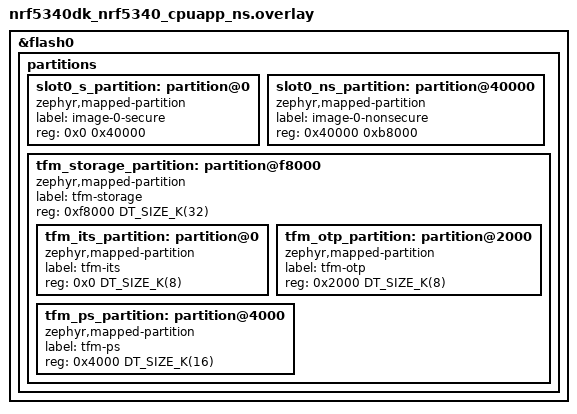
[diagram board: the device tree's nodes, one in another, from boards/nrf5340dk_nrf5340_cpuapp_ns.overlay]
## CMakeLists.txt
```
#
# Copyright (c) 2021 Nordic Semiconductor ASA
#
# SPDX-License-Identifier: LicenseRef-Nordic-5-Clause
#

cmake_minimum_required(VERSION 3.20.0)

find_package(Zephyr REQUIRED HINTS $ENV{ZEPHYR_BASE})

project(persistent_key)

target_sources(app PRIVATE
  src/main.c
  src/init.c
)
```

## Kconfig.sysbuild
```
#
# Copyright (c) 2025 Nordic Semiconductor
#
# SPDX-License-Identifier: LicenseRef-Nordic-5-Clause
#

config PARTITION_MANAGER
	default n if !(SOC_SERIES_NRF91 && BOARD_IS_NON_SECURE)

source "share/sysbuild/Kconfig"
```

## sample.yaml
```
sample:
  description: |
    This sample demonstrates persistent key usage using the PSA Crypto API.
  name: Persistent key usage sample

common:
  sysbuild: true
  tags:
    - introduction
    - psa
    - sysbuild
    - ci_samples_crypto
    - crypto
  harness: console
  harness_config:
    type: multi_line
    regex:
      - ".*Example finished successfully!.*"

tests:
  sample.persistent_key_usage.tf-m:
    tags:
      - ci_samples_tfm
    platform_allow:
      - nrf5340dk/nrf5340/cpuapp/ns
      - nrf54l15dk/nrf54l15/cpuapp/ns
      - nrf54l15dk/nrf54l10/cpuapp/ns
      - nrf54lm20dk/nrf54lm20a/cpuapp/ns
      - nrf54lm20dk/nrf54lm20b/cpuapp/ns
      - nrf54lv10dk/nrf54lv10a/cpuapp/ns
      - nrf54lc10dk/nrf54lc10a/cpuapp/ns
      - nrf7120dk/nrf7120/cpuapp/ns
      - nrf9151dk/nrf9151/ns
    integration_platforms:
      - nrf5340dk/nrf5340/cpuapp/ns
      - nrf54l15dk/nrf54l15/cpuapp/ns
      - nrf54lm20dk/nrf54lm20a/cpuapp/ns
      - nrf54lm20dk/nrf54lm20b/cpuapp/ns
      - nrf54lv10dk/nrf54lv10a/cpuapp/ns
      - nrf54lc10dk/nrf54lc10a/cpuapp/ns
      - nrf7120dk/nrf7120/cpuapp/ns
      - nrf9151dk/nrf9151/ns
  sample.persistent_key_usage.ironside_se:
    tags:
      - ci_samples_sdfw
    platform_allow:
      - nrf54h20dk/nrf54h20/cpuapp
    integration_platforms:
      - nrf54h20dk/nrf54h20/cpuapp
  sample.persistent_key_usage.secure_storage:
    platform_allow:
      - nrf52840dk/nrf52840
      - nrf5340dk/nrf5340/cpuapp
      - nrf9151dk/nrf9151
      - nrf54l15dk/nrf54l15/cpuapp
      - nrf54lm20dk/nrf54lm20a/cpuapp
      - nrf54lm20dk/nrf54lm20b/cpuapp
      - nrf54lv10dk/nrf54lv10a/cpuapp
      - nrf54lc10dk/nrf54lc10a/cpuapp
      - nrf54l15dk/nrf54l10/cpuapp
      - nrf54l15dk/nrf54l05/cpuapp
      - nrf7120dk/nrf7120/cpuapp
    integration_platforms:
      - nrf52840dk/nrf52840
      - nrf5340dk/nrf5340/cpuapp
      - nrf9151dk/nrf9151
      - nrf54l15dk/nrf54l15/cpuapp
      - nrf54lm20dk/nrf54lm20a/cpuapp
      - nrf54lm20dk/nrf54lm20b/cpuapp
      - nrf54lv10dk/nrf54lv10a/cpuapp
      - nrf54lc10dk/nrf54lc10a/cpuapp
      - nrf7120dk/nrf7120/cpuapp
  sample.persistent_key_usage.trusted_storage:
    extra_args:
      - CONFIG_SECURE_STORAGE=n
      - CONFIG_TRUSTED_STORAGE=y
    platform_allow:
      - nrf52840dk/nrf52840
      - nrf5340dk/nrf5340/cpuapp
      - nrf9151dk/nrf9151
      - nrf54l15dk/nrf54l15/cpuapp
      - nrf54lm20dk/nrf54lm20a/cpuapp
      - nrf54lm20dk/nrf54lm20b/cpuapp
      - nrf54lv10dk/nrf54lv10a/cpuapp
      - nrf54lc10dk/nrf54lc10a/cpuapp
      - nrf54l15dk/nrf54l10/cpuapp
      - nrf54l15dk/nrf54l05/cpuapp
      - nrf7120dk/nrf7120/cpuapp
    integration_platforms:
      - nrf52840dk/nrf52840
      - nrf5340dk/nrf5340/cpuapp
      - nrf9151dk/nrf9151
      - nrf54l15dk/nrf54l15/cpuapp
      - nrf54lm20dk/nrf54lm20a/cpuapp
      - nrf54lm20dk/nrf54lm20b/cpuapp
      - nrf54lv10dk/nrf54lv10a/cpuapp
      - nrf54lc10dk/nrf54lc10a/cpuapp
      - nrf7120dk/nrf7120/cpuapp
```

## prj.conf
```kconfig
#
# Copyright (c) 2024 Nordic Semiconductor ASA
#
# SPDX-License-Identifier: LicenseRef-Nordic-5-Clause
#
# The Zephyr CMSIS emulation assumes that ticks are ms, currently
CONFIG_SYS_CLOCK_TICKS_PER_SEC=1000

CONFIG_MAIN_STACK_SIZE=4096
CONFIG_HEAP_MEM_POOL_SIZE=4096
CONFIG_REBOOT=y

# Enable logging
CONFIG_CONSOLE=y
CONFIG_LOG=y

# Enable cryptographic features
CONFIG_PSA_CRYPTO=y
CONFIG_PSA_WANT_KEY_TYPE_AES=y
CONFIG_PSA_WANT_ALG_CTR=y
CONFIG_PSA_WANT_GENERATE_RANDOM=y
```

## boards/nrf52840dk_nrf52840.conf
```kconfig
#
# Copyright (c) 2024 Nordic Semiconductor ASA
#
# SPDX-License-Identifier: LicenseRef-Nordic-5-Clause

# Using hardware crypto accelerator
CONFIG_PSA_CRYPTO_DRIVER_OBERON=n
CONFIG_PSA_CRYPTO_DRIVER_CC3XX=y

# When TF-M is not in use, the Secure Storage subsystem provides the PSA Secure Storage API.
CONFIG_SECURE_STORAGE=y
# Use ChaCha20-Poly1305 instead of AES-GCM because the latter is not supported by CC310.
CONFIG_SECURE_STORAGE_ITS_TRANSFORM_AEAD_SCHEME_CHACHA20_POLY1305=n

CONFIG_FLASH=y
CONFIG_FLASH_PAGE_LAYOUT=y
CONFIG_FLASH_MAP=y
CONFIG_NVS=y
CONFIG_SETTINGS=y

CONFIG_MBEDTLS_ENABLE_HEAP=y
CONFIG_MBEDTLS_HEAP_SIZE=8192
```

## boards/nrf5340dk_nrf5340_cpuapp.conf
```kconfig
#
# Copyright (c) 2024 Nordic Semiconductor ASA
#
# SPDX-License-Identifier: LicenseRef-Nordic-5-Clause

# Using hardware crypto accelerator
CONFIG_PSA_CRYPTO_DRIVER_OBERON=n
CONFIG_PSA_CRYPTO_DRIVER_CC3XX=y

# When TF-M is not in use, the Secure Storage subsystem provides the PSA Secure Storage API.
CONFIG_SECURE_STORAGE=y

CONFIG_FLASH=y
CONFIG_FLASH_PAGE_LAYOUT=y
CONFIG_FLASH_MAP=y
CONFIG_NVS=y
CONFIG_SETTINGS=y

CONFIG_MBEDTLS_ENABLE_HEAP=y
CONFIG_MBEDTLS_HEAP_SIZE=8192
```

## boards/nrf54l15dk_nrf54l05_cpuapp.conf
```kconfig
#
# Copyright (c) 2024 Nordic Semiconductor ASA
#
# SPDX-License-Identifier: LicenseRef-Nordic-5-Clause
#
# Using hardware crypto accelerator
CONFIG_PSA_CRYPTO_DRIVER_OBERON=n
CONFIG_PSA_CRYPTO_DRIVER_CRACEN=y

# Use TRUSTED_STORAGE because this is a non-TF-M board target.
CONFIG_TRUSTED_STORAGE=y

CONFIG_FLASH=y
CONFIG_FLASH_PAGE_LAYOUT=y
CONFIG_FLASH_MAP=y
CONFIG_ZMS=y
CONFIG_SETTINGS=y

# Mbedtls configuration
CONFIG_MBEDTLS_ENABLE_HEAP=y
CONFIG_MBEDTLS_HEAP_SIZE=8192
```

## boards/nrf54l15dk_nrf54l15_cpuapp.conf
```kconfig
#
# Copyright (c) 2024 Nordic Semiconductor ASA
#
# SPDX-License-Identifier: LicenseRef-Nordic-5-Clause

# Using hardware crypto accelerator
CONFIG_PSA_CRYPTO_DRIVER_OBERON=n
CONFIG_PSA_CRYPTO_DRIVER_CRACEN=y

# When TF-M is not in use, the Secure Storage subsystem provides the PSA Secure Storage API.
CONFIG_SECURE_STORAGE=y

CONFIG_FLASH=y
CONFIG_FLASH_PAGE_LAYOUT=y
CONFIG_FLASH_MAP=y
CONFIG_ZMS=y
CONFIG_SETTINGS=y

CONFIG_MBEDTLS_ENABLE_HEAP=y
CONFIG_MBEDTLS_HEAP_SIZE=8192
```

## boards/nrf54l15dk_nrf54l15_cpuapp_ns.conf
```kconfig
# Copyright (c) 2024 Nordic Semiconductor ASA
# SPDX-License-Identifier: LicenseRef-Nordic-5-Clause

CONFIG_TFM_ITS_ENCRYPTED=y
```

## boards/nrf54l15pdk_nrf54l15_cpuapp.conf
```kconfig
#
# Copyright (c) 2024 Nordic Semiconductor ASA
#
# SPDX-License-Identifier: LicenseRef-Nordic-5-Clause
#
# Using hardware crypto accelerator
CONFIG_PSA_CRYPTO_DRIVER_OBERON=n
CONFIG_PSA_CRYPTO_DRIVER_CRACEN=y

# Use TRUSTED_STORAGE because this is a non-TF-M board target.
CONFIG_TRUSTED_STORAGE=y

CONFIG_FLASH=y
CONFIG_FLASH_PAGE_LAYOUT=y
CONFIG_FLASH_MAP=y
CONFIG_ZMS=y
CONFIG_SETTINGS=y
```

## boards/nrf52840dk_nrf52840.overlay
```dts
/*
 * Copyright (c) 2026 Nordic Semiconductor ASA
 *
 * SPDX-License-Identifier: LicenseRef-Nordic-5-Clause
 */

/*
 * Hardware Unique Key partition for nRF52840.
 * This partition is used to store the HUK in flash since nRF52840
 * does not have a KMU. The partition is placed at the end of flash
 * and its size matches FPROTECT_BLOCK_SIZE (4KB).
 *
 * The default storage_partition overlaps with this location, so we
 * delete it and recreate it at a different address.
 */

/delete-node/ &storage_partition;

&flash0 {
	partitions {
		storage_partition: partition@fd000 {
			compatible = "zephyr,mapped-partition";
			label = "storage";
			reg = <0x000fd000 0x00002000>;
		};

		hw_unique_key_partition: partition@ff000 {
			compatible = "zephyr,mapped-partition";
			label = "";
			reg = <0x000ff000 0x00001000>;
		};
	};
};
```

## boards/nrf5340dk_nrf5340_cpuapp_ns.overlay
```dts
/delete-node/ &boot_partition;
/delete-node/ &slot0_partition;
/delete-node/ &slot1_partition;
/delete-node/ &storage_partition;

/delete-node/ &tfm_its_partition;
/delete-node/ &tfm_otp_partition;
/delete-node/ &tfm_ps_partition;

&flash0 {
	partitions {
		slot0_s_partition: partition@0 {
			compatible = "zephyr,mapped-partition";
			label = "image-0-secure";
			reg = <0x0 0x40000>;
		};

		slot0_ns_partition: partition@40000 {
			compatible = "zephyr,mapped-partition";
			label = "image-0-nonsecure";
			reg = <0x40000 0xb8000>;
		};

		tfm_storage_partition: partition@f8000 {
			compatible = "zephyr,mapped-partition";
			label = "tfm-storage";
			reg = <0xf8000 DT_SIZE_K(32)>;
			ranges = <0x0 0xf8000 DT_SIZE_K(32)>;
			#address-cells = <1>;
			#size-cells = <1>;

			tfm_its_partition: partition@0 {
				compatible = "zephyr,mapped-partition";
				label = "tfm-its";
				reg = <0x0 DT_SIZE_K(8)>;
			};

			tfm_otp_partition: partition@2000 {
				compatible = "zephyr,mapped-partition";
				label = "tfm-otp";
				reg = <0x2000 DT_SIZE_K(8)>;
			};

			tfm_ps_partition: partition@4000 {
				compatible = "zephyr,mapped-partition";
				label = "tfm-ps";
				reg = <0x4000 DT_SIZE_K(16)>;
			};
		};
	};
};

/*
 * This layout redefines the flash partition map, dropping partitions that the
 * upstream nordic-tz-secure/-nonsecure descriptors reference. Remove the
 * descriptors so they do not hold dangling phandles (restores the behaviour
 * from before the descriptors were introduced).
 */
/ {
	/delete-node/ nordic-tz-secure;
	/delete-node/ nordic-tz-nonsecure;
};
```

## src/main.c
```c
/*
 * Copyright (c) 2021 Nordic Semiconductor ASA
 *
 * SPDX-License-Identifier: LicenseRef-Nordic-5-Clause
 */

#include <zephyr/kernel.h>
#include <zephyr/sys/printk.h>
#include <zephyr/logging/log.h>
#include <stdio.h>
#include <psa/crypto.h>

#ifdef CONFIG_BUILD_WITH_TFM
#include <tfm_ns_interface.h>
#endif

#include "init.h"

#define APP_SUCCESS	    (0)
#define APP_ERROR	    (-1)
#define APP_SUCCESS_MESSAGE "Example finished successfully!"
#define APP_ERROR_MESSAGE   "Example exited with error!"

#define PRINT_HEX(p_label, p_text, len)                                                            \
	({                                                                                         \
		LOG_INF("---- %s (len: %u): ----", p_label, len);                                  \
		LOG_HEXDUMP_INF(p_text, len, "Content:");                                          \
		LOG_INF("---- %s end  ----", p_label);                                             \
	})

LOG_MODULE_REGISTER(persistent_key_usage, LOG_LEVEL_DBG);

/* ====================================================================== */
/*			Global variables/defines for the persistent key  example	  */

/* The key id for the persistent key. The macros PSA_KEY_ID_USER_MIN and
 * PSA_KEY_ID_USER_MAX define the range of freely available key ids.
 */
#define SAMPLE_PERS_KEY_ID				PSA_KEY_ID_USER_MIN
#define SAMPLE_KEY_TYPE					PSA_KEY_TYPE_AES
#define SAMPLE_ALG					PSA_ALG_CTR
#define NRF_CRYPTO_EXAMPLE_PERSISTENT_KEY_MAX_TEXT_SIZE (100)

static psa_key_id_t key_id;

/* Below text is used as plaintext for encryption/decryption */
static uint8_t m_plain_text[NRF_CRYPTO_EXAMPLE_PERSISTENT_KEY_MAX_TEXT_SIZE] = {
	"Example string to demonstrate basic usage of a persistent key."};

static uint8_t m_encrypted_text[PSA_CIPHER_ENCRYPT_OUTPUT_SIZE(
	SAMPLE_KEY_TYPE, SAMPLE_ALG, NRF_CRYPTO_EXAMPLE_PERSISTENT_KEY_MAX_TEXT_SIZE)];
static uint8_t m_decrypted_text[NRF_CRYPTO_EXAMPLE_PERSISTENT_KEY_MAX_TEXT_SIZE];
/* ====================================================================== */

int crypto_init(void)
{
	psa_status_t status;

#if	defined(CONFIG_TRUSTED_STORAGE_BACKEND_AEAD_KEY_DERIVE_FROM_HUK) || \
	defined(CONFIG_SECURE_STORAGE_ITS_TRANSFORM_AEAD_KEY_PROVIDER_HUK_LIBRARY)
	write_huk();
#endif

	/* Initialize PSA Crypto */
	status = psa_crypto_init();
	if (status != PSA_SUCCESS) {
		return APP_ERROR;
	}

	return APP_SUCCESS;
}

int crypto_finish(void)
{
	psa_status_t status;

	/* Destroy the key handle */
	status = psa_destroy_key(key_id);
	if (status != PSA_SUCCESS) {
		LOG_INF("psa_destroy_key failed! (Error: %d)", status);
		return APP_ERROR;
	}

	return APP_SUCCESS;
}

int generate_persistent_key(void)
{
	psa_status_t status;

	LOG_INF("Generating random persistent AES key...");

	/* Configure the key attributes */
	psa_key_attributes_t key_attributes = PSA_KEY_ATTRIBUTES_INIT;

	psa_set_key_usage_flags(&key_attributes, PSA_KEY_USAGE_ENCRYPT | PSA_KEY_USAGE_DECRYPT);
	psa_set_key_algorithm(&key_attributes, SAMPLE_ALG);
	psa_set_key_type(&key_attributes, SAMPLE_KEY_TYPE);
	psa_set_key_bits(&key_attributes, 128);

	/* Persistent key specific settings */
	psa_set_key_lifetime(&key_attributes, PSA_KEY_LIFETIME_PERSISTENT);
	psa_set_key_id(&key_attributes, SAMPLE_PERS_KEY_ID);

	/* Generate a random AES key with persistent lifetime. The key can be used for
	 * encryption/decryption using the key_id.
	 */
	status = psa_generate_key(&key_attributes, &key_id);
	if (status != PSA_SUCCESS) {
		LOG_INF("psa_generate_key failed! (Error: %d)", status);
		return APP_ERROR;
	}

	/* Make sure the key is not in memory anymore, has the same affect then resetting the device
	 */
	status = psa_purge_key(key_id);
	if (status != PSA_SUCCESS) {
		LOG_INF("psa_purge_key failed! (Error: %d)", status);
		return APP_ERROR;
	}

	/* After the key handle is acquired the attributes are not needed */
	psa_reset_key_attributes(&key_attributes);

	LOG_INF("Persistent key generated successfully!");

	return APP_SUCCESS;
}

int use_persistent_key(void)
{
	uint32_t olen;
	psa_status_t status;

	status = psa_cipher_encrypt((psa_key_id_t)SAMPLE_PERS_KEY_ID, SAMPLE_ALG, m_plain_text,
				    sizeof(m_plain_text), m_encrypted_text,
				    sizeof(m_encrypted_text), &olen);
	if (status != PSA_SUCCESS) {
		LOG_INF("psa_cipher_encrypt failed! (Error: %d)", status);
		return APP_ERROR;
	}

	LOG_INF("Encryption successful!");
	PRINT_HEX("Plaintext", m_plain_text, sizeof(m_plain_text));
	PRINT_HEX("Encrypted text", m_encrypted_text, sizeof(m_encrypted_text));

	status = psa_cipher_decrypt((psa_key_id_t)SAMPLE_PERS_KEY_ID, SAMPLE_ALG, m_encrypted_text,
				    sizeof(m_encrypted_text), m_decrypted_text,
				    sizeof(m_decrypted_text), &olen);
	if (status != PSA_SUCCESS) {
		LOG_INF("psa_cipher_decrypt failed! (Error: %d)", status);
		return APP_ERROR;
	}

	PRINT_HEX("Decrypted text", m_decrypted_text, sizeof(m_decrypted_text));

	/* Check the validity of the decryption */
	if (memcmp(m_decrypted_text, m_plain_text,
		   NRF_CRYPTO_EXAMPLE_PERSISTENT_KEY_MAX_TEXT_SIZE) != 0) {
		LOG_INF("Error: Decrypted text doesn't match the plaintext");
		return APP_ERROR;
	}

	LOG_INF("Decryption successful!");

	return APP_SUCCESS;
}

int main(void)
{
	int status;

	LOG_INF("Starting persistent key example...");

	status = crypto_init();
	if (status != APP_SUCCESS) {
		LOG_INF(APP_ERROR_MESSAGE);
		return APP_ERROR;
	}

	status = generate_persistent_key();
	if (status != APP_SUCCESS) {
		LOG_INF(APP_ERROR_MESSAGE);
		return APP_ERROR;
	}

	status = use_persistent_key();
	if (status != APP_SUCCESS) {
		LOG_INF(APP_ERROR_MESSAGE);
		return APP_ERROR;
	}

	status = crypto_finish();
	if (status != APP_SUCCESS) {
		LOG_INF(APP_ERROR_MESSAGE);
		return APP_ERROR;
	}

	LOG_INF(APP_SUCCESS_MESSAGE);

	return APP_SUCCESS;
}
```

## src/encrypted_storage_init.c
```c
/*
 * Copyright (c) 2023 Nordic Semiconductor ASA
 *
 * SPDX-License-Identifier: LicenseRef-Nordic-5-Clause
 */

#include "settings/settings_file.h"
#include <zephyr/device.h>
#include <zephyr/fs/fs.h>
#include <zephyr/fs/littlefs.h>
#include <zephyr/logging/log.h>

#define STORAGE_PARTITION    storage_partition
#define STORAGE_PARTITION_ID FIXED_PARTITION_ID(STORAGE_PARTITION)

LOG_MODULE_REGISTER(persistent_key_usage_encrypted_storage, LOG_LEVEL_DBG);

/* LittleFS work area strcut */
FS_LITTLEFS_DECLARE_DEFAULT_CONFIG(cstorage);
static struct fs_mount_t littlefs_mnt = {
	.type = FS_LITTLEFS,
	.fs_data = &cstorage,
	.storage_dev = (void *)STORAGE_PARTITION_ID,
	.mnt_point = "/0",
};

static int setup_settings_backend(void)
{
	int rc;

	rc = fs_mount(&littlefs_mnt);
	if (rc != 0) {
		LOG_ERR("%s failed (ret %d)", __func__, rc);
		return rc;
	}
	rc = settings_subsys_init();
	if (rc != 0) {
		LOG_ERR("%s failed (ret %d)", __func__, rc);
		return rc;
	}

	return 0;
}

SYS_INIT(setup_settings_backend, APPLICATION, CONFIG_APPLICATION_INIT_PRIORITY);

#ifdef CONFIG_ENCRYPTED_STORAGE_BACKEND_AEAD_KEY_DERIVE_FROM_HUK
#include <nrf_cc3xx_platform.h>
#include <hw_unique_key.h>

#ifndef HUK_HAS_KMU
#include <zephyr/sys/reboot.h>
#endif

int write_huk(void)
{
	if (!hw_unique_key_are_any_written()) {
		LOG_INF("Writing random keys to KMU\n");
		int result = hw_unique_key_write_random();

		if (result != HW_UNIQUE_KEY_SUCCESS) {
			LOG_ERR("hw_unique_key_write_random returned error: %d\n", result);
			return 0;
		}
		LOG_INF("Success!\n\n");
#if !defined(HUK_HAS_KMU)
		/* Reboot to allow the bootloader to load the key into CryptoCell. */
		sys_reboot(0);
#endif /* !defined(HUK_HAS_KMU) */
	}

	return 0;
}
#endif /* CONFIG_ENCRYPTED_STORAGE_BACKEND_AEAD_KEY_DERIVE_FROM_HUK */
```

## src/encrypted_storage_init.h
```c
/*
 * Copyright (c) 2023 Nordic Semiconductor ASA
 *
 * SPDX-License-Identifier: LicenseRef-Nordic-5-Clause
 */

#ifndef __ENCRYPTED_STORAGE_INIT_H_
#define __ENCRYPTED_STORAGE_INIT_H_

/* In case a HUK ist used for the encrypted_storage key */
#ifdef CONFIG_ENCRYPTED_STORAGE_BACKEND_AEAD_KEY_DERIVE_FROM_HUK
int write_huk(void);
#endif /* CONFIG_ENCRYPTED_STORAGE_BACKEND_AEAD_KEY_DERIVE_FROM_HUK */

#endif /* __ENCRYPTED_STORAGE_INIT_H_ */
```

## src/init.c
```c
/*
 * Copyright (c) 2023 Nordic Semiconductor ASA
 *
 * SPDX-License-Identifier: LicenseRef-Nordic-5-Clause
 */

#include <zephyr/device.h>
#include <zephyr/logging/log.h>
#include <zephyr/settings/settings.h>

LOG_MODULE_DECLARE(persistent_key_usage, LOG_LEVEL_DBG);

#ifdef CONFIG_TRUSTED_STORAGE_STORAGE_BACKEND_SETTINGS

static int setup_settings_backend(void)
{
	int rc = settings_subsys_init();

	if (rc != 0) {
		LOG_ERR("%s failed (ret %d)", __func__, rc);
		return rc;
	}

	return 0;
}

SYS_INIT(setup_settings_backend, APPLICATION, CONFIG_APPLICATION_INIT_PRIORITY);

#endif /* CONFIG_TRUSTED_STORAGE_STORAGE_BACKEND_SETTINGS */

#if	defined(CONFIG_TRUSTED_STORAGE_BACKEND_AEAD_KEY_DERIVE_FROM_HUK) || \
	defined(CONFIG_SECURE_STORAGE_ITS_TRANSFORM_AEAD_KEY_PROVIDER_HUK_LIBRARY)

#include <hw_unique_key.h>

#ifndef HUK_HAS_KMU
#include <zephyr/sys/reboot.h>
#endif

int write_huk(void)
{
	if (!hw_unique_key_are_any_written()) {
		LOG_INF("Writing random keys to KMU\n");
		int result = hw_unique_key_write_random();

		if (result != HW_UNIQUE_KEY_SUCCESS) {
			LOG_ERR("hw_unique_key_write_random returned error: %d\n", result);
			return 0;
		}
		LOG_INF("Success!\n\n");
#ifndef HUK_HAS_KMU
		/* Reboot to allow the bootloader to load the key into CryptoCell. */
		sys_reboot(0);
#endif
	}

	return 0;
}
#endif
```

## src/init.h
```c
/*
 * Copyright (c) 2023 Nordic Semiconductor ASA
 *
 * SPDX-License-Identifier: LicenseRef-Nordic-5-Clause
 */

#ifndef __INIT_H_
#define __INIT_H_

int write_huk(void);

#endif
```

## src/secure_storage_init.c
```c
/*
 * Copyright (c) 2023 Nordic Semiconductor ASA
 *
 * SPDX-License-Identifier: LicenseRef-Nordic-5-Clause
 */

#include "settings/settings_file.h"
#include <zephyr/device.h>
#include <zephyr/logging/log.h>

LOG_MODULE_REGISTER(persistent_key_usage_secure_storage, LOG_LEVEL_DBG);

static int setup_settings_backend(void)
{
	int rc = settings_subsys_init();

	if (rc != 0) {
		LOG_ERR("%s failed (ret %d)", __func__, rc);
		return rc;
	}

	return 0;
}

SYS_INIT(setup_settings_backend, APPLICATION, CONFIG_APPLICATION_INIT_PRIORITY);

#ifdef CONFIG_SECURE_STORAGE_BACKEND_AEAD_KEY_DERIVE_FROM_HUK
#include <nrf_cc3xx_platform.h>
#include <hw_unique_key.h>

#ifndef HUK_HAS_KMU
#include <zephyr/sys/reboot.h>
#endif

int write_huk(void)
{
	if (!hw_unique_key_are_any_written()) {
		LOG_INF("Writing random keys to KMU\n");
		int result = hw_unique_key_write_random();

		if (result != HW_UNIQUE_KEY_SUCCESS) {
			LOG_ERR("hw_unique_key_write_random returned error: %d\n", result);
			return 0;
		}
		LOG_INF("Success!\n\n");
#if !defined(HUK_HAS_KMU)
		/* Reboot to allow the bootloader to load the key into CryptoCell. */
		sys_reboot(0);
#endif /* !defined(HUK_HAS_KMU) */
	}

	return 0;
}
#endif /* CONFIG_SECURE_STORAGE_BACKEND_AEAD_KEY_DERIVE_FROM_HUK */
```

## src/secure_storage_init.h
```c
/*
 * Copyright (c) 2023 Nordic Semiconductor ASA
 *
 * SPDX-License-Identifier: LicenseRef-Nordic-5-Clause
 */

#ifndef __SECURE_STORAGE_INIT_H_
#define __SECURE_STORAGE_INIT_H_

/* In case a HUK ist used for the secure_storage key */
#ifdef CONFIG_SECURE_STORAGE_BACKEND_AEAD_KEY_DERIVE_FROM_HUK
int write_huk(void);
#endif /* CONFIG_SECURE_STORAGE_BACKEND_AEAD_KEY_DERIVE_FROM_HUK */

#endif /* __SECURE_STORAGE_INIT_H_ */
```

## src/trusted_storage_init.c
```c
/*
 * Copyright (c) 2023 Nordic Semiconductor ASA
 *
 * SPDX-License-Identifier: LicenseRef-Nordic-5-Clause
 */

#include "settings/settings_file.h"
#include <zephyr/device.h>
#include <zephyr/logging/log.h>

LOG_MODULE_REGISTER(persistent_key_usage_trusted_storage, LOG_LEVEL_DBG);

static int setup_settings_backend(void)
{
	int rc = settings_subsys_init();

	if (rc != 0) {
		LOG_ERR("%s failed (ret %d)", __func__, rc);
		return rc;
	}

	return 0;
}

SYS_INIT(setup_settings_backend, APPLICATION, CONFIG_APPLICATION_INIT_PRIORITY);

#ifdef CONFIG_TRUSTED_STORAGE_BACKEND_AEAD_KEY_DERIVE_FROM_HUK
#include <hw_unique_key.h>

#ifndef HUK_HAS_KMU
#include <zephyr/sys/reboot.h>
#endif

int write_huk(void)
{
	if (!hw_unique_key_are_any_written()) {
		LOG_INF("Writing random keys to KMU\n");
		int result = hw_unique_key_write_random();

		if (result != HW_UNIQUE_KEY_SUCCESS) {
			LOG_ERR("hw_unique_key_write_random returned error: %d\n", result);
			return 0;
		}
		LOG_INF("Success!\n\n");
#if !defined(HUK_HAS_KMU)
		/* Reboot to allow the bootloader to load the key into CryptoCell. */
		sys_reboot(0);
#endif /* !defined(HUK_HAS_KMU) */
	}

	return 0;
}
#endif /* CONFIG_TRUSTED_STORAGE_BACKEND_AEAD_KEY_DERIVE_FROM_HUK */
```

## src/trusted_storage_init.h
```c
/*
 * Copyright (c) 2023 Nordic Semiconductor ASA
 *
 * SPDX-License-Identifier: LicenseRef-Nordic-5-Clause
 */

#ifndef __TRUSTED_STORAGE_INIT_H_
#define __TRUSTED_STORAGE_INIT_H_

/* In case a HUK ist used for the trusted_storage key */
#ifdef CONFIG_TRUSTED_STORAGE_BACKEND_AEAD_KEY_DERIVE_FROM_HUK
int write_huk(void);
#endif /* CONFIG_TRUSTED_STORAGE_BACKEND_AEAD_KEY_DERIVE_FROM_HUK */

#endif /* __TRUSTED_STORAGE_INIT_H_ */
```
